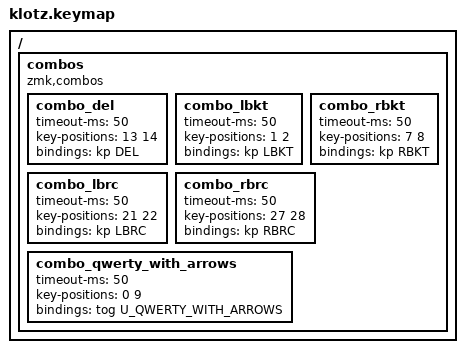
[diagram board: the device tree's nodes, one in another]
// Copyright 2021 Manna Harbour
// https://github.com/manna-harbour/miryoku

#include "../miryoku/custom_config.h"
#include "../miryoku/mapping/34/ferris.h"
#include "../miryoku/miryoku.dtsi"

/ {
    combos {
        compatible = "zmk,combos";
        combo_del {
            timeout-ms = <50>;
            key-positions = <13 14>;
            bindings = <&kp DEL>;
        };
        combo_lbkt { // [
            timeout-ms = <50>;
            key-positions = <1 2>;
            bindings = <&kp LBKT>;
        };
        combo_rbkt { // ]
            timeout-ms = <50>;
            key-positions = <7 8>;
            bindings = <&kp RBKT>;
        };
        combo_lbrc { // {
            timeout-ms = <50>;
            key-positions = <21 22>;
            bindings = <&kp LBRC>;
        };
        combo_rbrc { // }
            timeout-ms = <50>;
            key-positions = <27 28>;
            bindings = <&kp RBRC>;
        };
        combo_qwerty_with_arrows {
            timeout-ms = <50>;
            key-positions = <0 9>;
            bindings = <&tog U_QWERTY_WITH_ARROWS>;
        };
    };
};
